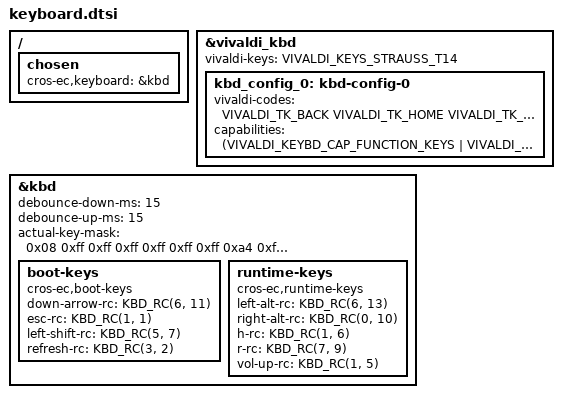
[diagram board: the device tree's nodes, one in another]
/* Copyright 2026 The ChromiumOS Authors
 * Use of this source code is governed by a BSD-style license that can be
 * found in the LICENSE file.
 */

/ {
	chosen {
		cros-ec,keyboard = &kbd;
	};
};

&vivaldi_kbd {
	vivaldi-keys = <VIVALDI_KEYS_STRAUSS_T14>;

	kbd_config_0: kbd-config-0 {
		vivaldi-codes = <
			VIVALDI_TK_BACK               /* T1  = F1  */
			VIVALDI_TK_HOME               /* T2  = F2  */
			VIVALDI_TK_OVERVIEW           /* T3  = F3  */
			VIVALDI_TK_FULLSCREEN         /* T4  = F4  */
			VIVALDI_TK_SNAPSHOT           /* T5  = F5  */
			VIVALDI_TK_BRIGHTNESS_DOWN    /* T6  = F6  */
			VIVALDI_TK_BRIGHTNESS_UP      /* T7  = F7  */
			VIVALDI_TK_KBD_BKLIGHT_TOGGLE /* T8  = F8  */
			VIVALDI_TK_MICMUTE            /* T9  = F9  */
			VIVALDI_TK_VOL_MUTE           /* T10 = F10 */
			VIVALDI_TK_VOL_DOWN           /* T11 = F11 */
			VIVALDI_TK_VOL_UP             /* T12 = F12 */
			VIVALDI_TK_ACCESSIBILITY      /* T13 = F13 */
			VIVALDI_TK_DICTATE            /* T14 = F14 */
		>;
		capabilities = <(VIVALDI_KEYBD_CAP_FUNCTION_KEYS |
				VIVALDI_KEYBD_CAP_SCRNLOCK_KEY |
				VIVALDI_KEYBD_CAP_ASSISTANT_KEY)>;
	};
};

&kbd {
	debounce-down-ms = <15>;
	debounce-up-ms = <15>;
	actual-key-mask = <
		0x08	/* C0 */
		0xff	/* C1 */
		0xff	/* C2 */
		0xff	/* C3 */
		0xff	/* C4 */
		0xff	/* C5 */
		0xff	/* C6 */
		0xa4	/* C7 */
		0xff	/* C8 */
		0xff	/* C9 */
		0x55	/* C10 */
		0xff	/* C11 */
		0xca	/* C12 */
		0x40	/* C13 */
		0x0a	/* C14 */
		0x40	/* C15 */
		0xff	/* C16 */
		0xc4	/* C17 */
	>;

	boot-keys {
		compatible = "cros-ec,boot-keys";
		down-arrow-rc = <KBD_RC(6, 11)>;
		esc-rc = <KBD_RC(1, 1)>;
		left-shift-rc = <KBD_RC(5, 7)>;
		refresh-rc = <KBD_RC(3, 2)>;
	};

	runtime-keys {
		compatible = "cros-ec,runtime-keys";
		left-alt-rc = <KBD_RC(6, 13)>;
		right-alt-rc = <KBD_RC(0, 10)>;
		h-rc = <KBD_RC(1, 6)>;
		r-rc = <KBD_RC(7, 9)>;
		vol-up-rc = <KBD_RC(1, 5)>;
	};
};
